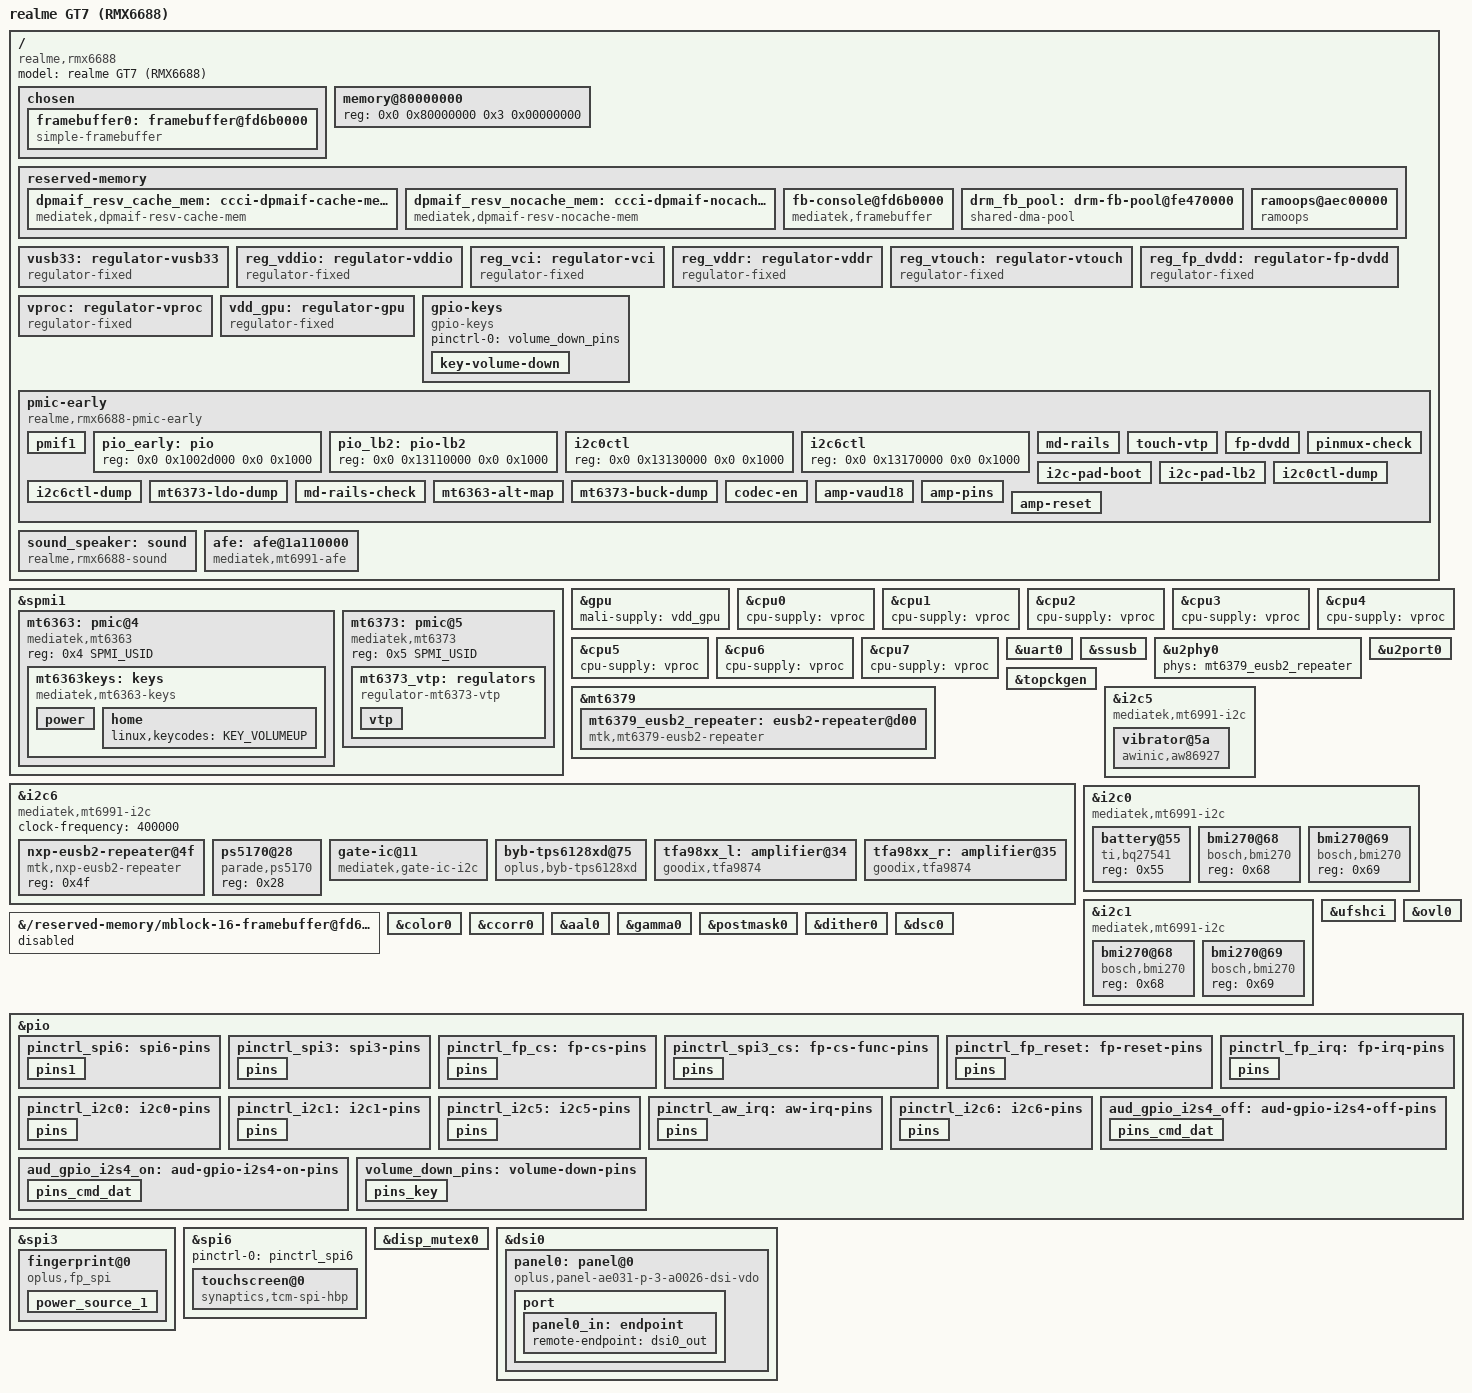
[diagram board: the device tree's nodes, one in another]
// SPDX-License-Identifier: (GPL-2.0 OR MIT)
/*
 * realme GT7 (RMX6688) -- MT6991 (Dimensity 9400+), 12 GB LPDDR5X + 256 GB UFS.
 *
 * First-boot bring-up target: reach userspace and print the kernel log to the
 * panel.  There is no display driver here -- the MediaTek bootloader lights up
 * the DSI panel for its boot logo and leaves it scanning out, so the kernel
 * borrows that live framebuffer through simplefb and puts fbcon on it.  That
 * only holds as long as nothing reprograms the display path, which is why no
 * OVL/DSI/mmsys nodes are described yet.
 */

/dts-v1/;

#include "mt6991.dtsi"
#include <dt-bindings/input/input.h>
#include <dt-bindings/pinctrl/mt6991-pinfunc.h>
#include "mt6991-realme-rmx6688-connectivity.dtsi"
#include "mt6991-realme-rmx6688-pcie.dtsi"
#include "mt6991-realme-connfem-fem.dtsi"
#include "mt6991-realme-connfem-sku.dtsi"
#include "mt6991-realme-rmx6688-bt.dtsi"
#include "mt6991-realme-rmx6688-modem.dtsi"
#include "mt6991-realme-rmx6688-scp.dtsi"

/ {
	model = "realme GT7 (RMX6688)";
	compatible = "realme,rmx6688", "mediatek,mt6991";

	chosen {
		#address-cells = <2>;
		#size-cells = <2>;
		ranges;

		/*
		 * LK's chip-id tag, from the vendor FDT's /chosen/atag,chipid.
		 * The LVTS driver reads sw_ver to decide whether the A0 sensor-id
		 * remap applies; non-zero means production silicon, no remap.
		 */
		atag,chipid = <0x18000000 0x57130000 0x8a0000 0x1ca0000 0x1000000>;

		/* LK boot-mode tag (stock /chosen/atag,boot): normal boot. */
		atag,boot = <0x10000000 0x2080041 0x00 0x2000000>;

		/*
		 * Live bootloader framebuffer, from /chosen/atag,videolfb in the
		 * vendor FDT: fb_base 0xfd6b0000, 60.00 Hz, 0x2940000 of VRAM
		 * (three 1280x2800 buffers plus alignment slack), panel
		 * "panel_ae031_p_3_a0026_dsi_vdo".
		 *
		 * The tag carries no geometry, so width/height come from the
		 * panel's DRM mode (1280x2800) and the format is the 32 bpp the
		 * MTK bootloader uses.  reg covers one frame, not all of VRAM.
		 * If the first boot paints skewed diagonal stripes, the
		 * bootloader is running 24 bpp instead: switch format to
		 * "r8g8b8" and stride to <3840>.
		 */
		framebuffer0: framebuffer@fd6b0000 {
			compatible = "simple-framebuffer";
			reg = <0x0 0xfd6b0000 0x0 (5120 * 2800)>;
			width = <1280>;
			height = <2800>;
			stride = <5120>;
			format = "x8r8g8b8";
			status = "okay";
		};
	};

	memory@80000000 {
		device_type = "memory";
		/* 12 GB: 0x80000000 - 0x380000000 */
		reg = <0x0 0x80000000 0x3 0x00000000>;
	};

	reserved-memory {
		#address-cells = <2>;
		#size-cells = <2>;
		ranges;

		/*
		 * Carries over every fixed reservation from the vendor FDT.
		 * These hold firmware that is live while Linux runs -- BL31,
		 * TEE, GenieZone, SSPM, MCUPM, SCP, ADSP, modem -- so the kernel
		 * must not allocate from them.
		 */
		#include "mt6991-realme-rmx6688-resmem.dtsi"

		/*
		 * DPMAIF (MD data path) DMA buffers.  The vendor reserves these
		 * dynamically (alloc-ranges), so they are not in the static FDT;
		 * sizes/alignment copied from the vendor mt6991.dts.
		 */
		dpmaif_resv_cache_mem: ccci-dpmaif-cache-memory {
			compatible = "mediatek,dpmaif-resv-cache-mem";
			size = <0 0x00190000>;	/* 1638400 B for 1 rxq */
			alignment = <0 0x10000>;
			alloc-ranges = <0 0x40000000 0 0xf0000000>;
		};

		dpmaif_resv_nocache_mem: ccci-dpmaif-nocache-memory {
			compatible = "mediatek,dpmaif-resv-nocache-mem";
			no-map;
			size = <0 0x0050000>;	/* 327680 B */
			alignment = <0 0x10000>;
			alloc-ranges = <0 0x40000000 0 0xf0000000>;
		};

		/*
		 * The vendor reserved the whole bootloader VRAM (0xfd6b0000 +
		 * 0x2940000, no-map).  We need part of it for the DRM
		 * framebuffer: the display SMMU (managed by the bootloader,
		 * not by mainline) only translates the addresses the
		 * bootloader mapped, so a normal CMA buffer faults and the
		 * EXDMA freezes.  Disable the vendor reservation and replace
		 * it with two regions:
		 *  - the first buffer keeps simplefb / the console alive
		 *  - the second buffer becomes a shared-dma-pool for the DRM
		 *    dumb buffer so EXDMA3 fetches a mapped address.
		 */
		fb-console@fd6b0000 {
			compatible = "mediatek,framebuffer";
			reg = <0x0 0xfd6b0000 0x0 0x00dc0000>;
			no-map;
		};

	drm_fb_pool: drm-fb-pool@fe470000 {
		compatible = "shared-dma-pool";
		/*
		 * OVL internal DMA pool for dummy/conversion buffers.
		 * One 12800x2800x4 framebuffer needs ~137 MiB but those
		 * are allocated from CMA, not here.  This pool is for
		 * the OVL driver's internal scratch allocations; 48 MiB
		 * provides headroom.
		 */
		reg = <0x0 0xfe470000 0x0 0x03000000>;
			/*
			 * Must be no-map: dma_init_coherent_memory() memremaps
			 * the region and the kernel refuses to alias System RAM.
			 */
			no-map;
		};

		/*
		 * Same region the vendor kernel uses for pstore, described as a
		 * mainline ramoops node.  This is the debugging channel that
		 * matters during bring-up: the log survives a reset, so after a
		 * failed boot you can reboot into Android and read the mainline
		 * panic out of /sys/fs/pstore/console-ramoops-0.
		 *
		 * Sizes mirror the vendor command line (ramoops.mem_address=
		 * 0xaec00000 mem_size=0x310000 console_size=0x200000
		 * pmsg_size=0x100000); record-size takes the remaining 64 KiB.
		 */
		ramoops@aec00000 {
			compatible = "ramoops";
			reg = <0x0 0xaec00000 0x0 0x310000>;
			/*
			 * Keeps the buffer out of the linear map, matching the
			 * vendor tree.  Without it pstore maps the region
			 * cacheable and a dirty line written back across a
			 * reset can eat the very log we booted to read.
			 */
			no-map;
			console-size = <0x200000>;
			pmsg-size = <0x100000>;
			record-size = <0x10000>;
		};
	};

	/*
	 * USB-C PHY rail.  The vendor tree takes vusb33 from the mt6373 PMIC
	 * (mt6373_vusb), which has no mainline driver; the bootloader leaves
	 * the rail up, so a fixed always-on regulator satisfies the mtu3
	 * driver's mandatory vusb33-supply without pretending to control it.
	 * Same approach as the MT6895 xaga port.
	 */
	vusb33: 	regulator-vusb33 {
		compatible = "regulator-fixed";
		regulator-name = "vusb33";
		regulator-min-microvolt = <3300000>;
		regulator-max-microvolt = <3300000>;
		regulator-always-on;
		regulator-boot-on;
	};

	/*
	 * DSI0 panel power supplies -- simplified regulators for bring-up.
	 * The real supply chain is: PMIC vddio(1.8V) / vci(3.0V), GPIO vddr.
	 * These will be replaced once we have proper PMIC/GPIO regulator drivers.
	 */
	reg_vddio: regulator-vddio {
		compatible = "regulator-fixed";
		regulator-name = "vddio";
		regulator-min-microvolt = <1800000>;
		regulator-max-microvolt = <1800000>;
		regulator-always-on;
		regulator-boot-on;
	};

	reg_vci: regulator-vci {
		compatible = "regulator-fixed";
		regulator-name = "vci";
		regulator-min-microvolt = <3000000>;
		regulator-max-microvolt = <3000000>;
		regulator-always-on;
		regulator-boot-on;
	};

	reg_vddr: regulator-vddr {
		compatible = "regulator-fixed";
		regulator-name = "vddr";
		regulator-min-microvolt = <1800000>;
		regulator-max-microvolt = <1800000>;
		regulator-always-on;
		regulator-boot-on;
	};

		reg_vtouch: regulator-vtouch {
		compatible = "regulator-fixed";
		regulator-name = "vtouch";
		regulator-min-microvolt = <2800000>;
		regulator-max-microvolt = <2800000>;
		regulator-always-on;
		regulator-boot-on;
	};

	/*
	 * Fingerprint DVDD (MT6373 VFP, 3.0 V).  The rail itself is raised by
	 * mt6991-pmic-early over bare SWINF; this fixed regulator only gives the
	 * fingerprint driver a "dvdd" supply to request.  Once MT6373 has a real
	 * regulator driver, point dvdd-supply back at it.
	 */
	reg_fp_dvdd: regulator-fp-dvdd {
		compatible = "regulator-fixed";
		regulator-name = "fp_dvdd";
		regulator-min-microvolt = <3000000>;
		regulator-max-microvolt = <3000000>;
		regulator-always-on;
		regulator-boot-on;
	};

	/*
	 * CPU DVFS supply stub: mediatek-cpufreq-hw asks for a "cpu" supply on
	 * every CPU.  The real CPU voltage is stepped by the SoC's hardware
	 * DVFS, so a fixed always-on regulator is enough and silences the
	 * "supply cpu not found, using dummy regulator" warning.
	 */
	vproc: regulator-vproc {
		compatible = "regulator-fixed";
		regulator-name = "vproc";
		regulator-min-microvolt = <800000>;
		regulator-max-microvolt = <800000>;
		regulator-always-on;
	};

	/*
	 * GPU supply stub: panthor calls dev_pm_opp_set_regulators() with
	 * names[] = { "mali" } and refuses to probe without it.  The real VGPU
	 * rail is left powered as the bootloader set it.  min == max is
	 * required by regulator-fixed.
	 */
	vdd_gpu: regulator-gpu {
		compatible = "regulator-fixed";
		regulator-name = "vdd_gpu";
		regulator-min-microvolt = <750000>;
		regulator-max-microvolt = <750000>;
		regulator-always-on;
	};

	/*
	 * Volume-down button.  The power and volume-up buttons come from the
	 * MT6363 PMIC (see &mt6363 below); volume-down is not wired to the
	 * SoC KPD matrix but to GPIO11 as a plain active-low EINT.  Marked as
	 * a wakeup source so it can leave s2idle (the polled MT6363 keys
	 * cannot arm a PMIC IRQ on MT6991).
	 */
	gpio-keys {
		compatible = "gpio-keys";
		pinctrl-names = "default";
		pinctrl-0 = <&volume_down_pins>;

		key-volume-down {
			label = "Volume Down";
			gpios = <&pio 11 GPIO_ACTIVE_LOW>;
			linux,code = <KEY_VOLUMEDOWN>;
			linux,input-type = <EV_KEY>;
			wakeup-source;
			debounce-interval = <32>;
		};
	};
};

/*
 * MT6363 main PMIC (SPMI USID 4, on the same bus as the MT6379 charger).
 * Only the keys are described here: PWRKEY -> KEY_POWER and HOMEKEY ->
 * KEY_VOLUMEUP (the physical volume-up line is wired to the PMIC, not to an
 * SoC GPIO).  The driver polls TOPSTATUS because the MT6991 SPMI controller
 * runs without an interrupt domain.
 */
/*
 * MT6373 (second PMIC, SPMI USID 5).  The full vendor regulator driver
 * (drivers/regulator/mt6373-regulator.c) is still in the tree but is not
 * built: it talks through devm_regmap_init_spmi_ext(), and every 16-bit
 * extended register access on this SoC times out in the mainline PMIF
 * driver.  The rails it would own are raised instead by the early sequence
 * node below (mt6991-pmic-early), which speaks the bare SWINF handshake.
 *
 * VTP is the touch panel's analogue rail (3.1 V).  See the pmic-early node
 * for the actual register writes; avdd-supply still points at &reg_vtouch
 * until the kernel-raised rail has been proven on its own.
 */
&spmi1 {
	mt6363: pmic@4 {
		compatible = "mediatek,mt6363";
		reg = <0x4 SPMI_USID>;
		#address-cells = <0>;
		#size-cells = <0>;

		mt6363keys: keys {
			compatible = "mediatek,mt6363-keys";

			power {
				linux,keycodes = <KEY_POWER>;
				wakeup-source;
			};

			home {
				linux,keycodes = <KEY_VOLUMEUP>;
			};
		};

	};

	mt6373: pmic@5 {
		compatible = "mediatek,mt6373";
		reg = <0x5 SPMI_USID>;
		#address-cells = <1>;
		#size-cells = <0>;

		mt6373_vtp: regulators {
			compatible = "regulator-mt6373-vtp";

			vtp {
				regulator-compatible = "VTP";
				regulator-name = "vtp";
				regulator-min-microvolt = <3100000>;
				regulator-max-microvolt = <3100000>;
				regulator-always-on;
			};
		};
	};
};

/*
 * Early board rails, applied by mt6991-pmic-early at subsys_initcall.
 *
 * The sequences live here (not in the driver) because the mainline PMIF
 * controller cannot finish a 16-bit extended register access on MT6991 --
 * every one times out on SWINF_WFVLDCLR -- so they go over a bare SWINF
 * handshake on the same PMIF window init-rootfs.c used to mmap.
 *
 * subsys_initcall runs strictly before any device_initcall driver can
 * register, i.e. before the SPI6 controller, so the touch panel's first
 * probe sees AVDD already up and no longer needs an unbind/rebind.
 *
 * avdd-supply deliberately keeps pointing at the &reg_vtouch stub for now:
 * leave that safety net in place until a boot has been seen with the panel
 * coming up on the kernel-raised rail alone.
 */
/ {
	pmic-early {
		compatible = "realme,rmx6688-pmic-early";
		#address-cells = <2>;
		#size-cells = <2>;
		/* 1:1 map: the children's reg are already CPU physical */
		ranges;

		/*
		 * PMIF window 0x1c01a000 (spmi1), SWINF channel 2 at ACC +0x880 --
		 * the same bus, channel and command encoding the init writer used
		 * (see md-rails below), and the same channel the kernel SPMI
		 * driver drives later.
		 */
		pmif1: pmif1 {
			reg = <0x0 0x1c01a000 0x0 0x1000>;
			mediatek,swinf-offset = <0x880>;
		};

		/*
		 * SoC PIO (pinctrl@1002d000).  No mediatek,swinf-offset, so the
		 * driver reads/writes it as plain MMIO -- this is the window
		 * init-rootfs.c used for the GPIO9 "codec-en" pin.
		 */
		pio_early: pio {
			reg = <0x0 0x1002d000 0x0 0x1000>;
		};

		/*
		 * pinctrl register bank 12 ("lb2", 0x13110000).  IES/PD/PU/SMT/DRV
		 * are NOT in bank 0: mt8196's field tables give each pin group its
		 * own i_base (pinctrl-mt8196.c), and pins 99/100 (i2c0) plus
		 * 104/105 (i2c6) all live in bank 12.  Everything dumped from
		 * pio_early above is bank 0, so the earlier "IES=0" conclusion
		 * read unrelated pins.  MODE/DIR/DI/DO really are bank 0 though,
		 * which is why the MODE decode (0x11 for 104/105) was right.
		 *
		 * Bit positions in this bank:
		 *   IES 0x0050 / PD 0x0080 / PU 0x0090
		 *        pin99=bit9, pin100=bit12, pin104=bit11, pin105=bit14
		 *   SMT 0x00c0
		 *        pin99=bit6, pin100=bit9, pin104=bit8, pin105=bit11
		 *   DRV 0x0000   pin99=bits18-20, pin100=bits27-29, pin104=bits24-26
		 *   DRV 0x0010   pin105=bits3-5
		 */
		pio_lb2: pio-lb2 {
			reg = <0x0 0x13110000 0x0 0x1000>;
		};

		i2c0ctl: i2c0ctl {
			reg = <0x0 0x13130000 0x0 0x1000>;
		};

		i2c6ctl: i2c6ctl {
			reg = <0x0 0x13170000 0x0 0x1000>;
		};

		/*
		 * MT6363 modem rails (SPMI USID 4), moved here from
		 * init-rootfs.c's md_rails_up() on 2026-10-17.  The bootloader
		 * normally brings them up, so the state check below matches and
		 * nothing is written; the steps are the fallback repair sequence
		 * for "modem powered but rails down".
		 *   VBUCK4 0x250 = 120 -> 0.75 V (md-vsram)
		 *   VBUCK5 0x251 = 112 -> 0.70 V (md-vdigrf)
		 *   VBUCK6 0x252 = 128 -> 0.80 V (md-vmodem)
		 *
		 * Vendor offsets only: the mainline mt6363-regulator.h map
		 * (0x210/0x220) does not exist on this silicon and writes there
		 * are silently ignored (AUDIO_NOTES 13.3).
		 *
		 * When the kernel can really own these rails (fixed register map
		 * + working PMIF extended access -> CONFIG_REGULATOR_MT6363 and
		 * DTS vbuck4/5/6 regulator nodes), delete this child; see
		 * doc/PMIC_PORT_HANDOFF.md 1.1.
		 */
		md-rails {
			mediatek,bus = <&pmif1>;
			mediatek,usid = <0x04>;
			mediatek,state = <0x240 0x70 0x70>,
					 <0x250 0xff 0x78>,
					 <0x251 0xff 0x70>,
					 <0x252 0xff 0x80>;
			mediatek,steps = <0x142a 0xffffffff 0x43 0>,
					 <0x142b 0xffffffff 0x55 0>,
					 <0x250 0xffffffff 120 0>,
					 <0x251 0xffffffff 112 0>,
					 <0x252 0xffffffff 128 0>,
					 <0x241 0xffffffff 0x70 0>,
					 <0x142a 0xffffffff 0x00 0>,
					 <0x142b 0xffffffff 0x00 5000>;
		};

		/*
		 * MT6373 VTP LDO (SPMI USID 5) -- the touch panel's analogue rail.
		 *   RG_LDO_VTP_EN  0x1d23  bit0 = enable, bit1 = low-power (clear it)
		 *   RG_VTP_VOSEL   0x1e35  [3:0] = ldo_volt_table1 index 12 = 3.1 V
		 * Steps are <reg mask value delay_us>; mask ~0 = plain write.
		 */
		touch-vtp {
			mediatek,bus = <&pmif1>;
			mediatek,usid = <0x05>;
			mediatek,state = <0x1d23 0x01 0x01>,
					 <0x1e35 0xff 0x0c>;
			mediatek,steps = <0x1e35 0xffffffff 0x0c 0>,
					 <0x1d23 0x00000003 0x00000001 20000>;
		};

		/*
		 * MT6373 VFP LDO (SPMI USID 5) -- fingerprint DVDD, 3.0 V.
		 *   RG_LDO_VFP_EN  0x1d15  bit0 = enable, bit1 = low-power (clear)
		 *   RG_VFP_VOSEL   0x1e31  [3:0] = ldo_volt_table1 index 11 = 3.0 V
		 */
		fp-dvdd {
			mediatek,bus = <&pmif1>;
			mediatek,usid = <0x05>;
			mediatek,state = <0x1d15 0x01 0x01>,
					 <0x1e31 0x0f 0x0b>;
			mediatek,steps = <0x1e31 0xffffffff 0x0b 0>,
					 <0x1d15 0x00000003 0x00000001 20000>;
		};


		/*
		 * Read-only probes (mediatek,state with no mediatek,steps).
		 * They log the current state and never write, so they are safe
		 * to carry in every boot while a question is still open.
		 *
		 * i2c6 (SCL=GPIO104, SDA=GPIO105) NAKs every device in mainline
		 * while i2c0/i2c1 on the same west i2c wrapper answer, so either
		 * the pinmux did not land or the bus is unpowered.  MODE for pin
		 * N lives at 0x300 + (N/8)*0x10, 4 bits per pin, so 104/105 share
		 * 0x3d0 (nibble 0 and nibble 1); SCL6/SDA6 are function 1, hence
		 * an expected byte of 0x11.
		 */
		pinmux-check {
			mediatek,bus = <&pio_early>;
			mediatek,state = <0x3d0 0x000000ff 0x00000011>;
		};

		/*
		 * Bootloader pad state for the I2C pins, sampled at 88 ms
		 * before pinctrl claims them (i2c6 probes at ~7 s).  Android
		 * never reconfigures these, so this is exactly the config the
		 * running phone has.  mt8196 field tables (pinctrl-mt8196.c):
		 *   IES 0x0050  bit9/12 = pin99/100 (i2c0), bit11/14 = pin104/105 (i2c6)
		 *   PD  0x0080  same bit positions
		 *   PU  0x00c0  same bit positions
		 *   DRV 0x0000  bit18/27 = pin99/100, bit24 (pin104); 0x0010 bit3 (pin105)
		 */
		i2c-pad-boot {
			mediatek,bus = <&pio_early>;
			mediatek,state = <0x0050 0xffffffff 0x00000000>,   /* IES  99/100=bit9/12  104/105=bit11/14 */
					 <0x0080 0xffffffff 0x00000000>,   /* PD   same bits */
					 <0x00c0 0xffffffff 0x00000000>,   /* PU   same bits */
					 <0x0000 0xffffffff 0x00000000>,   /* DRV  bit18/27=99/100, bit24=104, 0x0010 bit3=105 */
					 <0x0010 0xffffffff 0x00000000>,   /* DRV  continued */
					 <0x03c0 0xffffffff 0x00000000>,   /* MODE pins 96-103 (99/100 at bit12/16) */
					 <0x03d0 0xffffffff 0x00000000>,   /* MODE pins 104-111 (104/105 at bit0/4) */
					 <0x0030 0xffffffff 0x00000000>,   /* DIR  99=bit3 100=bit4 104=bit8 105=bit9 */
					 <0x0130 0xffffffff 0x00000000>,   /* DOUT same bits */
					 <0x0230 0xffffffff 0x00000000>;   /* DIN  same bits */
		};

		/*
		 * The real pad config for i2c0 (99/100) and i2c6 (104/105),
		 * both in bank 12.  One register covers both buses, so i2c0
		 * is the control: whatever differs here is the i2c6 bug.
		 */
		i2c-pad-lb2 {
			mediatek,bus = <&pio_lb2>;
			mediatek,state = <0x0000 0xffffffff 0x00000000>,   /* DRV 99/100/104 */
					 <0x0010 0xffffffff 0x00000000>,   /* DRV 105 */
					 <0x0050 0xffffffff 0x00000000>,   /* IES 9/12/11/14 */
					 <0x0080 0xffffffff 0x00000000>,   /* PD  same */
					 <0x0090 0xffffffff 0x00000000>,   /* PU  same */
					 <0x00c0 0xffffffff 0x00000000>;   /* SMT 6/9/8/11 */
		};

		/*
		 * i2c0 (working) vs i2c6 (deaf) controller state, sampled twice:
		 * at 88 ms (bootloader) and again at 15 s via the late pass
		 * (after every i2c driver has probed).  Offsets are the
		 * mt6893/mt6991 layout in i2c-mt65xx.c.  IO_CONFIG 0x34
		 * selects the open-drain pad mode; DEBUGSTAT 0xe4 reflects the
		 * SCL/SDA levels the controller itself sees.
		 */
		i2c0ctl-dump {
			mediatek,bus = <&i2c0ctl>;
			mediatek,state = <0x00 0xffffffff 0x00000000>,   /* DATA_PORT */
					 <0x0c 0xffffffff 0x00000000>,   /* INTR_STAT */
					 <0x10 0xffffffff 0x00000000>,   /* CONTROL */
					 <0x20 0xffffffff 0x00000000>,   /* TIMING */
					 <0x28 0xffffffff 0x00000000>,   /* EXT_CONF */
					 <0x2c 0xffffffff 0x00000000>,   /* LTIMING */
					 <0x34 0xffffffff 0x00000000>,   /* IO_CONFIG */
					 <0x48 0xffffffff 0x00000000>,   /* CLOCK_DIV */
					 <0xe4 0xffffffff 0x00000000>;   /* DEBUGSTAT */
		};

		i2c6ctl-dump {
			mediatek,bus = <&i2c6ctl>;
			mediatek,state = <0x00 0xffffffff 0x00000000>,   /* DATA_PORT */
					 <0x0c 0xffffffff 0x00000000>,   /* INTR_STAT */
					 <0x10 0xffffffff 0x00000000>,   /* CONTROL */
					 <0x20 0xffffffff 0x00000000>,   /* TIMING */
					 <0x28 0xffffffff 0x00000000>,   /* EXT_CONF */
					 <0x2c 0xffffffff 0x00000000>,   /* LTIMING */
					 <0x34 0xffffffff 0x00000000>,   /* IO_CONFIG */
					 <0x48 0xffffffff 0x00000000>,   /* CLOCK_DIV */
					 <0xe4 0xffffffff 0x00000000>;   /* DEBUGSTAT */
		};

		/*
		 * NOTE (2026-10-14, negative result, do not redo):
		 * reading the MT pinctrl DI register (0x200 + (N/8)*0x10) does
		 * NOT reveal an I2C line's level once the pin is muxed to the
		 * I2C function -- the input path is handed to the peripheral.
		 * Measured: i2c6 (GPIO104/105) read 0x00, but so did i2c0
		 * (GPIO99/100, mask bits 3/4) and i2c1 (GPIO200/201) on buses
		 * that demonstrably work.  The probe sequences i2c0-lines /
		 * i2c1-lines / i2c6-lines that used this are removed; use a
		 * real pad-mode read or a scope instead.
		 */

		/*
		 * Every MT6373 LDO enable byte (USID 5), from the vendor map in
		 * include/linux/regulator/mt6373-regulator.h.  Read-only, and the
		 * "want" is 0 so the printed value is the whole answer: bit0 is
		 * enable, bit1 is low-power mode.  The bootloader never powers the
		 * PMIC down across our hand-off, so this is a snapshot of what is
		 * actually live -- use it to spot an obviously-off rail that could
		 * be feeding the i2c6 devices.
		 */
		mt6373-ldo-dump {
			mediatek,bus = <&pmif1>;
			mediatek,usid = <0x05>;
			mediatek,state = <0x1b87 0x000000ff 0x00000000>,   /* VAUD18 */
					 <0x1b95 0x000000ff 0x00000000>,   /* VUSB */
					 <0x1ba3 0x000000ff 0x00000000>,   /* VAUX18 */
					 <0x1bb1 0x000000ff 0x00000000>,   /* VRF13_AIF */
					 <0x1bbf 0x000000ff 0x00000000>,   /* VRF18_AIF */
					 <0x1bcd 0x000000ff 0x00000000>,   /* VRFIO18_AIF */
					 <0x1c07 0x000000ff 0x00000000>,   /* VCN33_1 */
					 <0x1c15 0x000000ff 0x00000000>,   /* VCN33_2 */
					 <0x1c23 0x000000ff 0x00000000>,   /* VCN33_3 */
					 <0x1c31 0x000000ff 0x00000000>,   /* VCN18IO */
					 <0x1c3f 0x000000ff 0x00000000>,   /* VRF09_AIF */
					 <0x1c4d 0x000000ff 0x00000000>,   /* VRF12_AIF */
					 <0x1c87 0x000000ff 0x00000000>,   /* VANT18 */
					 <0x1ca3 0x000000ff 0x00000000>,   /* VEFUSE */
					 <0x1cb1 0x000000ff 0x00000000>,   /* VMCH */
					 <0x1cc0 0x000000ff 0x00000000>,   /* VMC */
					 <0x1cce 0x000000ff 0x00000000>,   /* VIBR */
					 <0x1d07 0x000000ff 0x00000000>,   /* VIO28 */
					 <0x1d15 0x000000ff 0x00000000>,   /* VFP */
					 <0x1d23 0x000000ff 0x00000000>,   /* VTP */
					 <0x1d31 0x000000ff 0x00000000>,   /* VSIM1 */
					 <0x1d40 0x000000ff 0x00000000>,   /* VSIM2 */
					 <0x1d87 0x000000ff 0x00000000>;   /* VSRAM_DIGRF_AIF */
		};

		/*
		 * MT6363 md rails (SPMI USID 4): the bootloader is known to bring
		 * these up; this read-only probe witnesses the state every boot, so
		 * a bootloader change or a broken md-rails repair shows up in
		 * dmesg.  vsel = uV / 6250, so 0.75/0.70/0.80 V are
		 * 120/112/128 = 0x78/0x70/0x80.
		 */
		md-rails-check {
			mediatek,bus = <&pmif1>;
			mediatek,usid = <0x04>;
			mediatek,state = <0x240 0x00000070 0x00000070>,
					 <0x250 0x000000ff 0x00000078>,
					 <0x251 0x000000ff 0x00000070>,
					 <0x252 0x000000ff 0x00000080>;
		};

		/*
		 * The mainline mt6363-regulator.h puts the buck enables at
		 * 0x210/0x213, while the vendor sequence (and the md rails above)
		 * uses 0x240/0x241/0x250-0x252; AUDIO_NOTES 13.3 says writes to
		 * the mainline map are silently ignored.  Read both so the map
		 * question is settled by the silicon rather than by argument;
		 * read-only, so probing an unmapped offset costs nothing.
		 */
		mt6363-alt-map {
			mediatek,bus = <&pmif1>;
			mediatek,usid = <0x04>;
			mediatek,state = <0x0210 0x000000ff 0x000000ff>,
					 <0x0213 0x000000ff 0x000000ff>,
					 <0x021c 0x000000ff 0x00000000>,
					 <0x0220 0x000000ff 0x00000000>,
					 <0x0221 0x000000ff 0x00000000>,
					 <0x0222 0x000000ff 0x00000000>;
		};

		/* MT6373 bucks: VBUCK0-7 share 0x240, VBUCK8-9 share 0x243.
		 * Boot snapshot has every buck on except VBUCK2, so also dump
		 * the per-buck VOSEL (0x24c-0x255) to see what VBUCK2 was
		 * configured for before it was left off. */
		mt6373-buck-dump {
			mediatek,bus = <&pmif1>;
			mediatek,usid = <0x05>;
			mediatek,state = <0x240 0x000000ff 0x00000000>,
					 <0x243 0x000000ff 0x00000000>,
					 <0x246 0x000000ff 0x00000000>,
					 <0x249 0x000000ff 0x00000000>,
					 <0x24c 0x000000ff 0x00000000>,
					 <0x24d 0x000000ff 0x00000000>,
					 <0x24e 0x000000ff 0x00000000>,
					 <0x24f 0x000000ff 0x00000000>,
					 <0x250 0x000000ff 0x00000000>,
					 <0x251 0x000000ff 0x00000000>,
					 <0x252 0x000000ff 0x00000000>,
					 <0x253 0x000000ff 0x00000000>,
					 <0x254 0x000000ff 0x00000000>,
					 <0x255 0x000000ff 0x00000000>;
		};


		/*
		 * SoC GPIO9 "codec-en": gates the MT6681 audio domain, which also
		 * feeds the i2c6 pull-ups and the speaker amps' VDD.  MODE
		 * 0x310 nibble 1 (pin 9 % 8), DIR 0x000 bit9, DO 0x100 bit9.
		 */
		codec-en {
			mediatek,bus = <&pio_early>;
			mediatek,state = <0x100 0x00000200 0x00000200>,
					 <0x000 0x00000200 0x00000200>;
			mediatek,steps = <0x310 0x000000f0 0x00000000 0>,
					 <0x000 0x00000200 0x00000200 0>,
					 <0x100 0x00000200 0x00000200 0>;
		};

		/*
		 * MT6373 PIO1/2, which carry the two TFA9874 RESETN lines
		 * (SPMI USID 5).  Registers from vendor pinctrl-mt6373.c:
		 *   PIO1 mode 0xc4[5:3], dir 0x88 bit7, dout 0xac bit7,
		 *        drv 0x29[7:4], smt 0x22 bit7
		 *   PIO2 mode 0xc7[2:0], dir 0x8b bit0, dout 0xaf bit0,
		 *        drv 0x2a[3:0], smt 0x23 bit0
		 * drv/smt are mandatory: an MTK pin with drv=0 does not actually
		 * drive, so a reset that only sets mode/dir/dout never reaches
		 * the amp.  Split into a state-guarded config and an always-run
		 * pulse, because a pulse leaves no resting state that proves it
		 * happened.  The amp rail (amp-vaud18) comes up first: the
		 * vendor driver only pulses RESETN with the supplies already on.
		 */
		amp-vaud18 {
			mediatek,bus = <&pmif1>;
			mediatek,usid = <0x05>;
			mediatek,state = <0x1b87 0x00000001 0x00000001>,
					 <0x1e89 0x000000ff 0x0000000c>;
			mediatek,steps = <0x1e89 0xffffffff 0x0c 0>,
					 <0x1b87 0x00000001 0x00000001 20000>;
		};

		amp-pins {
			mediatek,bus = <&pmif1>;
			mediatek,usid = <0x05>;
			mediatek,state = <0xc4 0x00000038 0x00000000>,
					 <0xc7 0x00000007 0x00000000>,
					 <0x88 0x00000080 0x00000080>,
					 <0x8b 0x00000001 0x00000001>,
					 <0x29 0x000000f0 0x000000f0>,
					 <0x2a 0x0000000f 0x0000000f>,
					 <0x22 0x00000080 0x00000080>,
					 <0x23 0x00000001 0x00000001>;
			mediatek,steps = <0xc4 0x00000038 0x00000000 0>,
					 <0x88 0x00000080 0x00000080 0>,
					 <0xc7 0x00000007 0x00000000 0>,
					 <0x8b 0x00000001 0x00000001 0>,
					 <0x29 0x000000f0 0x000000f0 0>,
					 <0x2a 0x0000000f 0x0000000f 0>,
					 <0x22 0x00000080 0x00000080 0>,
					 <0x23 0x00000001 0x00000001 0>;
		};

		amp-reset {
			mediatek,bus = <&pmif1>;
			mediatek,usid = <0x05>;
			mediatek,steps = <0xac 0x00000080 0x00000080 0>,
					 <0xaf 0x00000001 0x00000001 10000>,
					 <0xac 0x00000080 0x00000000 0>,
					 <0xaf 0x00000001 0x00000000 10000>;
		};
	};
};

&gpu {
	mali-supply = <&vdd_gpu>;
};

&cpu0 { cpu-supply = <&vproc>; };
&cpu1 { cpu-supply = <&vproc>; };
&cpu2 { cpu-supply = <&vproc>; };
&cpu3 { cpu-supply = <&vproc>; };
&cpu4 { cpu-supply = <&vproc>; };
&cpu5 { cpu-supply = <&vproc>; };
&cpu6 { cpu-supply = <&vproc>; };
&cpu7 { cpu-supply = <&vproc>; };

&uart0 {
	status = "okay";
};

/*
 * USB-C host (OTG) -- external devices through an OTG adapter (UART0's pads
 * need a factory cable, and the debug USB console is retired).  dr_mode is
 * redundant: the host-only kernel build forces HOST in mtu3_probe()
 * regardless.  Port 5 V comes from the MT6379 OTG boost, which
 * mt6379_charger.c turns on (CHG_TOP2 bit0) -- see the repeater node below
 * and its mediatek,host-* tuning.  maximum-speed = "high-speed" mirrors the
 * retail product, which disables SuperSpeed in software; the
 * "mediatek,eye-*" tuning values are the ones the vendor kernel ran the
 * device with (read from the booted vendor FDT).
 */
&ssusb {
	status = "okay";
	dr_mode = "host";
	maximum-speed = "high-speed";
	vusb33-supply = <&vusb33>;
};

&u2phy0 {
	status = "okay";
	/* eUSB2 repeater driven by the xsphy on every connect/replug */
	phys = <&mt6379_eusb2_repeater>;
};

/*
 * The MT6379 contains the eUSB2 repeater that sits between the SoC xsphy and
 * the USB-C connector.  It has no regmap of its own: the mt6379-charger SPMI
 * driver owns the MT6379 regmap, populates this child (of_platform_populate),
 * and the repeater driver picks up the parent regmap via dev_get_regmap().
 */
&mt6379 {
	mt6379_eusb2_repeater: eusb2-repeater@d00 {
		compatible = "mtk,mt6379-eusb2-repeater";
		reg = <0xd00>;
		#phy-cells = <0>;
		mediatek,rx-sqth = <0x5>;
		mediatek,pre-emphasis = <0x4>;
		mediatek,usb20-fs-sr = <0x7>;
		mediatek,eusb20-fsrx-hys-sel = <0x0>;
		mediatek,vrt-sel = <0x1>;
		mediatek,equalization = <0x4>;
		mediatek,discth = <0x6>;
		/* host-direction tuning, from the vendor FDT; applied by
		 * eusb2_host_prop_set() when mtu3 drives the port as host */
		mediatek,host-vrt-sel = <0x1>;
		mediatek,host-rx-sqth = <0x0>;
		mediatek,host-discth = <0x6>;
		mediatek,host-pre-emphasis = <0x2>;
		mediatek,host-equalization = <0x4>;
	};
};

&u2port0 {
	status = "okay";
	mediatek,eye-vrt = <0x07>;
	mediatek,eye-term = <0x07>;
	mediatek,refclk-sel;
	mediatek,chp-en-disable;
	mediatek,hsrx-vref-sel = <0x7>;
	mediatek,fs-cr = <0x7>;
	mediatek,discth = <11>;
	mediatek,rx-sqth = <2>;
	mediatek,rx-sqd = <2>;
	mediatek,rev6 = <3>;
};

/*
 * I2C6 -- hosts the NXP eUSB2 repeater (PTN36241 at 0x4f) which is on the
 * USB2 data path between the xsphy and the connector.  Without it the host
 * never enumerates the device.  The bootloader leaves the I2C controller and
 * the repeater running, so even if the pinctrl node is missing the driver
 * can still probe the chip and reconfigure it.
 *
 * The PS5170 (USB-C mux/redriver at 0x28) is also here but has no mainline
 * driver yet; the node is present so the hardware is documented.
 *
 * SCL = GPIO104, SDA = GPIO105 (vendor FDT scl-gpio-id / sda-gpio-id).
 */
/*
 * The vendor i2c driver forces clk_src=0 (clk26m) for every i2c controller.
 * Mainline leaves the topckgen "i2c_west"/"i2c_east"/... mux at whatever the
 * bootloader left (here 124.8 MHz), and the i2c timing then comes out wrong
 * (both buses fail: i2c0 times out, i2c6 NAKs).  Reparent all i2c muxes to
 * clk26m to match the vendor.
 */
&topckgen {
	assigned-clocks = <&topckgen CLK_TOP_I2C_P>,
			  <&topckgen CLK_TOP_I2C_EAST>,
			  <&topckgen CLK_TOP_I2C_WEST>,
			  <&topckgen CLK_TOP_I2C_NORTH>;
	assigned-clock-parents = <&clk26m>, <&clk26m>, <&clk26m>, <&clk26m>;
};

/*
 * I2C5: Awinic AW86927 haptic (0x5a).  Vendor FDT uses 1 MHz; keep 400 kHz
 * for bring-up margin.  Reset = GPIO18, IRQ = GPIO14 (vendor FDT).
 */
&i2c5 {
	status = "okay";
	compatible = "mediatek,mt6991-i2c";
	clock-frequency = <400000>;
	pinctrl-names = "default";
	pinctrl-0 = <&pinctrl_i2c5>;

	vibrator@5a {
		compatible = "awinic,aw86927";
		reg = <0x5a>;
		reset-gpios = <&pio 18 GPIO_ACTIVE_LOW>;
		interrupts-extended = <&pio 14 IRQ_TYPE_EDGE_FALLING>;
		pinctrl-names = "default";
		pinctrl-0 = <&pinctrl_aw_irq>;
	};
};

&i2c6 {
	status = "okay";
	compatible = "mediatek,mt6991-i2c";
	/* vendor FDT: clock-frequency = <0x61a80> = 400 kHz.  This was once
	 * dropped to 100 kHz only because i2c0's fuel gauge needed it; the
	 * 100 kHz fix belongs to i2c0 alone (bq27541 times out at 400 kHz),
	 * and both 100 kHz and 400 kHz leave the speaker amps NAK. */
	clock-frequency = <400000>;
	/*
	 * Deliberately NO pinctrl-names/pinctrl-0 here.
	 *
	 * The vendor FDT's i2c@13170000 node has no pinctrl either, and the
	 * Android log confirms pinmux-pins shows 104/105 as MUX UNCLAIMED:
	 * Android never claims these pads, so the bootloader's configuration
	 * (MODE=1, IES=0, PU=0, per i2c-pad-boot at 88 ms) is what actually
	 * serves the bus -- and that is exactly the state in which 0x75/0x34/
	 * 0x35 ACK.
	 *
	 * Our own claim (pinmux + bias-pull-up + input-enable) deviates from
	 * that known-good state.  input-enable alone was tried and did not
	 * fix the NACK, so drop the whole claim and mirror Android instead.
	 * pinctrl_i2c6 below stays defined for reference but is unreferenced.
	 */
	/* pinctrl-names = "default"; */

	nxp-eusb2-repeater@4f {
		compatible = "mtk,nxp-eusb2-repeater";
		reg = <0x4f>;
		#phy-cells = <0>;
		status = "okay";
	};

	ps5170@28 {
		compatible = "parade,ps5170";
		reg = <0x28>;
		status = "okay";
	};

	/*
	 * Devices present in the vendor FDT that were missing here until
	 * 2026-10-14 (found by diffing /root/mainline/fdt.dts.txt, the dump of
	 * the device tree the phone actually runs).  No mainline driver for
	 * either; the nodes exist so the addresses are enumerated and so the
	 * hardware map stops being lost.
	 *
	 * gate-ic@11 is mtk,gate-ic-i2c (drivers/misc/mediatek/gate_ic/
	 * rt4831a_drv.c) -- a Richtek display bias part.  Its probe needs a
	 * "gate-power" GPIO that the vendor node does not provide, so it does
	 * not bind on Android either.
	 *
	 * byb-tps6128xd@75 is a TI TPS6128x boost converter, 3350 mV / 4500 mA
	 * -- the most concrete candidate yet for the TFA98xx PVDD supply that
	 * §13 of doc/AUDIO_NOTES.md says is invisible to software.  The vendor
	 * driver (vendor/oplus/kernel/charger/v1/bob_ic/oplus_tps6128xd.c)
	 * only writes VOUTFLOOR/VOUTROOF/ILIM and never an enable bit, so the
	 * part is switched by a hardware EN pin.
	 *
	 * Not added: speaker_amp@5c/@5d (richtek,rt5512).  They are in the
	 * vendor FDT but NAK on Android too (doc/AUDIO_NOTES.md §10.3) while
	 * the tfa98xx pair ACKs, so the board is populated with the NXP amps
	 * and the Richtek ones are the other PCB variant.
	 */
	gate-ic@11 {
		compatible = "mediatek,gate-ic-i2c";
		reg = <0x11>;
		id = <0x06>;
		status = "okay";
	};

	byb-tps6128xd@75 {
		compatible = "oplus,byb-tps6128xd";
		reg = <0x75>;
		oplus,ic_type = <0x01>;
		oplus,ic_index = <0x00>;
		oplus,vout-mv = <0xd16>;	/* 3350 mV */
		oplus,ilim-ma = <0x1194>;	/* 4500 mA */
		status = "okay";
	};

	/*
	 * NXP TFA9874 smart speaker amplifiers (project "emira").
	 * Their reset lines live on the MT6373 PMIC pinctrl (gpio1/2), which has
	 * no mainline driver yet, so reset-gpios are omitted for now.
	 */
	tfa98xx_l: amplifier@34 {
		compatible = "goodix,tfa9874";
		reg = <0x34>;
		#sound-dai-cells = <0>;
		sound-name-prefix = "Left";
		status = "okay";
	};

	tfa98xx_r: amplifier@35 {
		compatible = "goodix,tfa9874";
		reg = <0x35>;
		#sound-dai-cells = <0>;
		sound-name-prefix = "Right";
		status = "okay";
	};
};

/*
 * I2C0: magnetometer (AKM AK09918 @0x0e) and ALS/proximity (AMS TCS3720
 * @0x39).  Neither has a mainline driver yet; the bus is brought up so they
 * can be probed once drivers are ported.
 */
&i2c0 {
	status = "okay";
	compatible = "mediatek,mt6991-i2c";
	clock-frequency = <100000>;
	pinctrl-names = "default";
	pinctrl-0 = <&pinctrl_i2c0>;

	/*
	 * Battery fuel gauge: TI bq27541 @ 0x55 (matches the i2c-0 0-0055
	 * device the vendor kernel enumerates).  The bq27xxx driver is built
	 * in; this node gives battery voltage/capacity/current/temp to
	 * userspace via the power_supply class.
	 */
	battery@55 {
		compatible = "ti,bq27541";
		reg = <0x55>;
		status = "okay";
	};
};

/*
 * I2C1: accelerometer + gyroscope, Bosch BMI2xx (vendor "bmi2xy").
 * Mainline has the IIO bmi270 driver (bosch,bmi260 / bosch,bmi270).
 */
&i2c1 {
	status = "okay";
	compatible = "mediatek,mt6991-i2c";
	clock-frequency = <400000>;
	pinctrl-names = "default";
	pinctrl-0 = <&pinctrl_i2c1>;

	bmi270@68 {
		compatible = "bosch,bmi270";
		reg = <0x68>;
		status = "okay";
	};

	bmi270@69 {
		compatible = "bosch,bmi270";
		reg = <0x69>;
		status = "okay";
	};
};

/* The gsensor bus may be i2c0 instead (oplus "i2c_num" mapping); try both. */
&i2c0 {
	bmi270@68 {
		compatible = "bosch,bmi270";
		reg = <0x68>;
		status = "okay";
	};

	bmi270@69 {
		compatible = "bosch,bmi270";
		reg = <0x69>;
		status = "okay";
	};
};

/*
 * UFS.  The HCI already works off the bootloader/ATF-configured state
 * (device reset done, scsi host, MCQ), so this node only hands the
 * driver the passive freq-table-hz it asks for -- it silences
 * "freq-table-hz property not specified" and is pure bookkeeping:
 * clk-scaling itself stays disabled because upstream models neither the
 * ufs_sel[_min|_max]_src muxes nor dvfsrc-vcore, which is exactly what
 * the driver's "Clk-scaling not ready" line reports.
 *
 * Deliberately absent: a ufsphy node.  Upstream phy-mtk-ufs predates
 * this SoC's mphy-ver PHY revisioning (the vendor driver reads
 * "mphy-ver" from DT); hooking it up would make ufs_mtk_mphy_power_on()
 * reprogram the PHY with mt8183-era sequences on link startup.  The
 * same reasoning keeps "mphy_rst" out of the resets list: asserting it
 * in ufs_mtk_host_reset() would knock the ATF-configured PHY back to
 * POR without any reconfigure step behind it.  The remaining probe
 * notices ("find ti,syscon-reset fail", the vreg "assuming enabled"
 * lines) are the same category: vestigial or unmodelable paths whose
 * absence is the safe configuration.
 */
 &ufshci {
	freq-table-hz = <273000000 499200000>, <0 0>, <0 0>, <0 0>, <0 0>,
			<0 0>, <0 0>, <0 0>, <0 0>, <0 0>;
};

&ovl0 {
	status = "okay";
	/*
	 * EXPERIMENT (DRM_CMA_SMMU_ISSUE.md option B): do NOT give the OVL a
	 * reserved coherent pool.  A coherent pool makes dma_alloc_attrs()
	 * return early on failure without ever falling back to CMA, so with
	 * only 48 MiB available every extra dumb buffer fails (screen
	 * flicker / scale-change freeze).  Without it, DRM allocations go to
	 * the 256 MiB CMA at 0xc2000000.
	 *
	 * The vendor runs EXDMA3 with mtk,smmu-dma-mode = "bypass", so the
	 * hardware may accept physical addresses directly.  If the display
	 * freezes instead, the bootloader-managed MM SMMU is translating
	 * and we need option A (take over the SMMU).
	 *
	 * Revert: restore "memory-region = <&drm_fb_pool>;".
	 */
	/* memory-region = <&drm_fb_pool>; */
};

/* Superseded by the fb-console + drm-fb-pool split above. */
&{/reserved-memory/mblock-16-framebuffer@fd6b0000} {
	status = "disabled";
};

&color0 {
	status = "okay";
};

&ccorr0 {
	status = "okay";
};

&aal0 {
	status = "okay";
};

&gamma0 {
	status = "okay";
};

&postmask0 {
	status = "okay";
};

&dither0 {
	status = "okay";
};

&dsc0 {
	status = "okay";
};

/* ---- Touchscreen (Synaptics S3910 on SPI6) ---- */

&pio {
	pinctrl_spi6: spi6-pins {
		pins1 {
			pinmux = <PINMUX_GPIO81__FUNC_SPI6_B_CLK>,
				 <PINMUX_GPIO82__FUNC_SPI6_B_CSB>,
				 <PINMUX_GPIO83__FUNC_SPI6_B_MO>,
				 <PINMUX_GPIO84__FUNC_SPI6_B_MI>;
			drive-strength = <MTK_DRIVE_8mA>;
		};
	};

	/* SPI3 fingerprint bus: CLK=106, CS=107, MOSI=108, MISO=109. */
	pinctrl_spi3: spi3-pins {
		pins {
			pinmux = <PINMUX_GPIO106__FUNC_SPI3_B_CLK>,
				 <PINMUX_GPIO107__FUNC_SPI3_B_CSB>,
				 <PINMUX_GPIO108__FUNC_SPI3_B_MO>,
				 <PINMUX_GPIO109__FUNC_SPI3_B_MI>;
			drive-strength = <MTK_DRIVE_4mA>;
		};
	};

	/* Fingerprint CS as GPIO (low) before the SPI function is claimed. */
	pinctrl_fp_cs: fp-cs-pins {
		pins {
			pinmux = <PINMUX_GPIO107__FUNC_GPIO107>;
			output-low;
			bias-disable;
		};
	};

	pinctrl_spi3_cs: fp-cs-func-pins {
		pins {
			pinmux = <PINMUX_GPIO107__FUNC_SPI3_B_CSB>;
			drive-strength = <MTK_DRIVE_4mA>;
		};
	};

	/* Fingerprint reset: GPIO115, idle low. */
	pinctrl_fp_reset: fp-reset-pins {
		pins {
			pinmux = <PINMUX_GPIO115__FUNC_GPIO115>;
			output-low;
		};
	};

	/* Fingerprint IRQ: GPIO114, input pull-down (vendor default). */
	pinctrl_fp_irq: fp-irq-pins {
		pins {
			pinmux = <PINMUX_GPIO114__FUNC_GPIO114>;
			input-enable;
			bias-pull-down;
		};
	};

	/* I2C0: SCL=GPIO99, SDA=GPIO100 (vendor scl/sda-gpio-id 0x63/0x64) */
	pinctrl_i2c0: i2c0-pins {
		pins {
			pinmux = <PINMUX_GPIO99__FUNC_SCL0>,
				 <PINMUX_GPIO100__FUNC_SDA0>;
			bias-pull-up;
			input-enable;
		};
	};

	/* I2C1: SCL=GPIO200, SDA=GPIO201 (vendor scl/sda-gpio-id 0xc8/0xc9) */
	pinctrl_i2c1: i2c1-pins {
		pins {
			pinmux = <PINMUX_GPIO200__FUNC_SCL1>,
				 <PINMUX_GPIO201__FUNC_SDA1>;
			bias-pull-up;
		};
	};

	/* I2C5: SCL=GPIO176, SDA=GPIO177 (vendor pinmux 0xb001/0xb101). */
	pinctrl_i2c5: i2c5-pins {
		pins {
			pinmux = <PINMUX_GPIO176__FUNC_SCL5>,
				 <PINMUX_GPIO177__FUNC_SDA5>;
			bias-pull-up;
			input-enable;
		};
	};

	/* AW86927 IRQ: GPIO14, input pull-up (vendor aw_irq_gpio_default). */
	pinctrl_aw_irq: aw-irq-pins {
		pins {
			pinmux = <PINMUX_GPIO14__FUNC_GPIO14>;
			input-enable;
			bias-pull-up;
		};
	};

	/* I2C6: SCL=GPIO104, SDA=GPIO105 (vendor scl/sda-gpio-id 0x68/0x69). */
	pinctrl_i2c6: i2c6-pins {
		pins {
			pinmux = <PINMUX_GPIO104__FUNC_SCL6>,
				 <PINMUX_GPIO105__FUNC_SDA6>;
			bias-pull-up;
			/* Open-drain bus: the controller must be able to read
			 * SDA back for the ACK bit.  mt8196 routes
			 * PIN_CONFIG_INPUT_ENABLE to PINCTRL_PIN_REG_IES
			 * (0x0050 bit11/bit14 here, via pinctrl-paris.c:289),
			 * and without it the input buffer stays off and every
			 * address reports ACKERR.  The bootloader sets this and
			 * Android never claims the pins, which is why only
			 * mainline saw the whole bus go deaf. */
			input-enable;
		};
	};

	/*
	 * AFE I2S4 pins: BCLK=GPIO95, LRCK=GPIO96, DIN=GPIO97 and the
	 * speaker data output DOUT=GPIO98.  The mt8196 AFE's DAPM
	 * pinctrl widget asks the afe device for the "aud-gpio-i2s4-*"
	 * states, so they have to be listed on the afe node below.
	 */
	aud_gpio_i2s4_off: aud-gpio-i2s4-off-pins {
		pins_cmd_dat {
			pinmux = <PINMUX_GPIO95__FUNC_GPIO95>,
				 <PINMUX_GPIO96__FUNC_GPIO96>,
				 <PINMUX_GPIO97__FUNC_GPIO97>,
				 <PINMUX_GPIO98__FUNC_GPIO98>;
			input-enable;
			bias-pull-down;
		};
	};

	aud_gpio_i2s4_on: aud-gpio-i2s4-on-pins {
		pins_cmd_dat {
			pinmux = <PINMUX_GPIO95__FUNC_I2SIN4_BCK>,
				 <PINMUX_GPIO96__FUNC_I2SIN4_LRCK>,
				 <PINMUX_GPIO97__FUNC_I2SIN4_DATA0>,
				 <PINMUX_GPIO98__FUNC_I2SOUT4_DATA0>;
			input-schmitt-enable;
			bias-disable;
		};
	};

	/* Volume-down EINT on GPIO11, active-low (vendor "volume_down_as_int"). */
	volume_down_pins: volume-down-pins {
		pins_key {
			pinmux = <PINMUX_GPIO11__FUNC_GPIO11>;
			input-enable;
			bias-pull-up;
		};
	};
};

/*
 * SPI3: Goodix under-display fingerprint.  Wiring from the vendor FDT:
 * CLK=GPIO106, CS=GPIO107, MOSI=GPIO108, MISO=GPIO109, IRQ=GPIO114,
 * RESET=GPIO115.  DVDD is MT6373 VFP (3.0 V), raised by pmic-early.
 */
&spi3 {
	status = "okay";

	fingerprint@0 {
		compatible = "oplus,fp_spi";
		reg = <0>;
		spi-max-frequency = <26000000>;
		spi-mode = <0>;
		spi-id = <3>;
		spi-irq = <114>;
		uff,gpio_irq = <&pio 114 0>;
		uff,gpio_reset = <&pio 115 0>;
		uff,gpio_cs = <&pio 107 0>;
		pinctrl-names = "default", "fp_spi_driver", "fp_cs_func", "gpio_cs_pull_down";
		pinctrl-0 = <&pinctrl_fp_irq>, <&pinctrl_fp_reset>, <&pinctrl_fp_cs>;
		pinctrl-1 = <&pinctrl_spi3>;
		pinctrl-2 = <&pinctrl_spi3_cs>;
		pinctrl-3 = <&pinctrl_fp_cs>;
		dvdd-supply = <&reg_fp_dvdd>;
		dvdd-config = <3000000 3000000 120000>;
		optical_irq_disable_flag = <1>;
		power-num = <1>;
		status = "okay";

		power_source_1 {
			power-mode = <1>;
			power-name = "dvdd";
			power-config = "dvdd-config";
			delay-time = <0>;
		};
	};
};

&spi6 {
	status = "okay";
	pinctrl-names = "default";
	pinctrl-0 = <&pinctrl_spi6>;

	touchscreen@0 {
		compatible = "synaptics,tcm-spi-hbp";
		reg = <0>;
		spi-max-frequency = <19000000>;

		interrupt-parent = <&pio>;
		interrupts = <7 IRQ_TYPE_LEVEL_LOW>;

		reset-gpios = <&pio 3 GPIO_ACTIVE_HIGH>;
		irq-gpios = <&pio 7 IRQ_TYPE_EDGE_FALLING>;

		/*
		 * Wired to the fixed stub, not the MT6373 VTP regulator: the
		 * kernel SPMI path cannot complete an EXT_REG_LONG (16-bit
		 * address) transaction to USID 5 ("failed to wait for
		 * SWINF_WFVLDCLR"), so the MT6373 regulator never registers and
		 * the panel would defer forever.  Pointing this back restores
		 * touch; the rail itself is raised by mt6991-pmic-early now.
		 */
		avdd-supply = <&reg_vtouch>;

		touchpanel,max-num-support = <10>;
		/*
		 * panel-coords is the raw sensor range reported by the IC
		 * (app_info max = 12799 x 27999, i.e. 10x the panel pixels);
		 * display-coords is the panel resolution in pixels.
		 */
		touchpanel,panel-coords = <12800 28000>;
		touchpanel,display-coords = <1280 2800>;
		/*
		 * Edge calibration: stretch the sensor's usable window to the
		 * full panel so touches near the border reach the very edge
		 * (the sensor's active area is slightly inset).
		 */
		touchpanel,cal-coords = <30 1264 16 2796>;
	};
};

&disp_mutex0 {
	status = "okay";
};

&dsi0 {
	status = "okay";

	panel0: panel@0 {
		compatible = "oplus,panel-ae031-p-3-a0026-dsi-vdo";
		reg = <0>;
		reset-gpios = <&pio 90 GPIO_ACTIVE_HIGH>;
		vddio-supply = <&reg_vddio>;
		vddr-supply = <&reg_vddr>;
		vci-supply = <&reg_vci>;

		port {
			panel0_in: endpoint {
				remote-endpoint = <&dsi0_out>;
			};
		};
	};
};

/*
 * Audio front-end (AFE).  MT6991 shares the MT8196 AFE register layout, so the
 * mainline mt8196 AFE driver drives it; only the clock wiring differs (vendor
 * mt6991 audiosys / cksys / vlp_cksys providers).  The clocks are named per
 * the vendor FDT and match aud_clks_mt6991[] in mt8196-afe-clk.c.
 */
/ {
	/*
	 * Speaker card: two TFA9873 mono amps on i2c6, both fed from AFE
	 * I2S output 4 (the vendor's spk-i2s-index 25/24 maps to
	 * I2SOUT4/I2SIN4).  Their RESETN lines are MT6373 PIO1/PIO2 and
	 * are pulsed by mt6991-pmic-early before i2c probe.
	 */
	sound_speaker: sound {
		compatible = "realme,rmx6688-sound";
		realme,codec-left = <&tfa98xx_l>;
		realme,codec-right = <&tfa98xx_r>;
		status = "okay";
	};

	afe: afe@1a110000 {
		compatible = "mediatek,mt6991-afe";
		reg = <0 0x1a110000 0 0x9000>;
		interrupts = <GIC_SPI 351 IRQ_TYPE_LEVEL_HIGH 0>;
		power-domains = <&scpsys MT6991_POWER_DOMAIN_AUDIO>;
		pinctrl-names = "aud-gpio-i2s4-off", "aud-gpio-i2s4-on";
		pinctrl-0 = <&aud_gpio_i2s4_off>;
		pinctrl-1 = <&aud_gpio_i2s4_on>;

		clocks = <&audiosys 0x71>, <&audiosys 0x73>,
			 <&cksys 0x50>, <&cksys 0x51>, <&cksys 0x5c>,
			 <&cksys 0x5d>, <&cksys 0x5e>, <&cksys 0x2d>,
			 <&vlp_cksys 0x28>, <&vlp_cksys 0x26>,
			 <&vlp_cksys 0x27>, <&vlp_cksys 0x25>;
		clock-names = "aud_apll1_clk", "aud_apll2_clk",
			      "ck_apll12_div_i2sin0", "ck_apll12_div_i2sin1",
			      "ck_apll12_div_fmi2s", "ck_apll12_div_tdmout_m",
			      "ck_apll12_div_tdmout_b", "ck_adsp_sel",
			      "vlp_mux_audio_int", "vlp_mux_aud_eng1",
			      "vlp_mux_aud_eng2", "vlp_mux_audio_h";
		status = "okay";
	};
};
